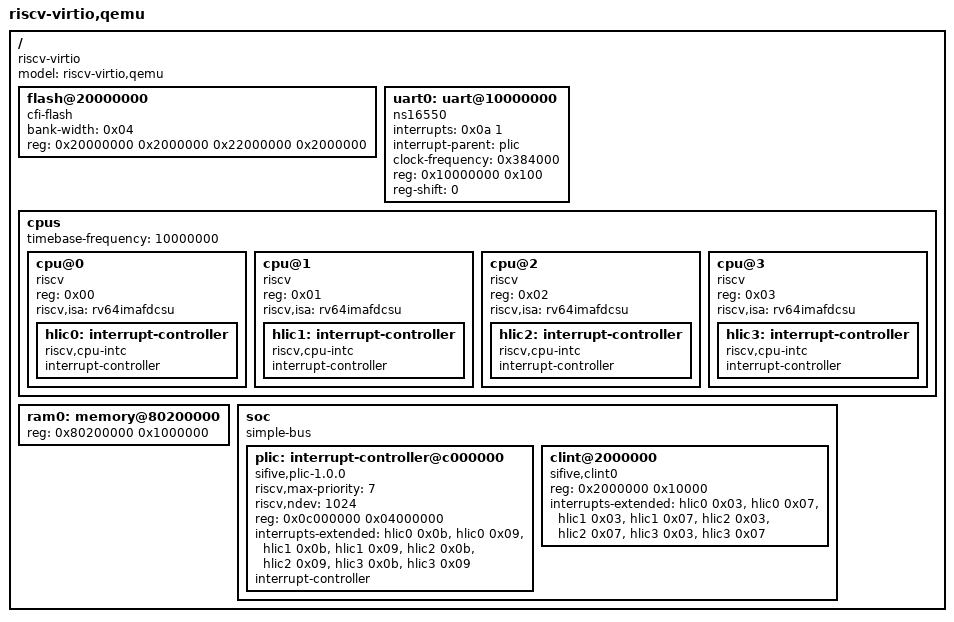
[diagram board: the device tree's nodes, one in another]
/*
 * Copyright (c) 2020 Cobham Gaisler AB
 *
 * SPDX-License-Identifier: Apache-2.0
 */

/*
 * This file is based on:
 *   qemu-system-riscv32 -machine virt,dumpdtb=virt.dtb -smp 8 -m 256
 *   dtc virt.dtb > virt.dtsi
 */

/dts-v1/;

/ {
	#address-cells = < 0x01 >;
	#size-cells = < 0x01 >;
	compatible = "riscv-virtio";
	model = "riscv-virtio,qemu";

	flash@20000000 {
		bank-width = < 0x04 >;
		reg = < 0x20000000 0x2000000 0x22000000 0x2000000 >;
		compatible = "cfi-flash";
	};

	uart0: uart@10000000 {
		interrupts = < 0x0a 1 >;
		interrupt-parent = < &plic >;
		clock-frequency = < 0x384000 >;
		reg = < 0x10000000 0x100 >;
		compatible = "ns16550";
		reg-shift = < 0 >;
	};

	cpus {
		#address-cells = < 0x01 >;
		#size-cells = < 0x00 >;
		timebase-frequency = < 10000000 >;

		cpu@0 {
			device_type = "cpu";
			reg = < 0x00 >;
			status = "okay";
			compatible = "riscv";
			riscv,isa = "rv64imafdcsu";

			hlic0: interrupt-controller {
				compatible = "riscv,cpu-intc";
				#address-cells = <0>;
				#interrupt-cells = < 0x01 >;
				interrupt-controller;
			};
		};

		cpu@1 {
			device_type = "cpu";
			reg = < 0x01 >;
			status = "okay";
			compatible = "riscv";
			riscv,isa = "rv64imafdcsu";

			hlic1: interrupt-controller {
				compatible = "riscv,cpu-intc";
				#address-cells = <0>;
				#interrupt-cells = < 0x01 >;
				interrupt-controller;
			};
		};

		cpu@2 {
			device_type = "cpu";
			reg = < 0x02 >;
			status = "okay";
			compatible = "riscv";
			riscv,isa = "rv64imafdcsu";

			hlic2: interrupt-controller {
				compatible = "riscv,cpu-intc";
				#address-cells = <0>;
				#interrupt-cells = < 0x01 >;
				interrupt-controller;
			};
		};

		cpu@3 {
			device_type = "cpu";
			reg = < 0x03 >;
			status = "okay";
			compatible = "riscv";
			riscv,isa = "rv64imafdcsu";

			hlic3: interrupt-controller {
				compatible = "riscv,cpu-intc";
				#address-cells = <0>;
				#interrupt-cells = < 0x01 >;
				interrupt-controller;
			};
		};
	};

	ram0: memory@80200000 {
		device_type = "memory";
		reg = < 0x80200000 0x1000000 >;
	};

	soc {
		#address-cells = < 0x01 >;
		#size-cells = < 0x01 >;
		compatible = "simple-bus";
		ranges;

		plic: interrupt-controller@c000000 {
			riscv,max-priority = <7>;
			riscv,ndev = < 1024 >;
			reg = <0x0c000000 0x04000000>;
			interrupts-extended = <
				&hlic0 0x0b &hlic0 0x09
				&hlic1 0x0b &hlic1 0x09
				&hlic2 0x0b &hlic2 0x09
				&hlic3 0x0b &hlic3 0x09
			>;
			interrupt-controller;
			compatible = "sifive,plic-1.0.0";
			#address-cells = < 0x00 >;
			#interrupt-cells = < 0x02 >;
		};

		clint@2000000 {
			compatible = "sifive,clint0";
			reg = <0x2000000 0x10000>;
			interrupts-extended = <&hlic0 0x03 &hlic0 0x07
					       &hlic1 0x03 &hlic1 0x07
					       &hlic2 0x03 &hlic2 0x07
					       &hlic3 0x03 &hlic3 0x07>;
		};
	};
};
